VERSION ""

NS_ :

BS_:

BU_: CAEB TCU GW
VAL_TABLE_ MotorRunningStatus 1 "MOTOR_RUNNING" 0 "MOTOR_OFF" ;

BO_ 2147536897 msgVD_GNSS_precision_position: 16 CAEB
 SG_ sigVD_GNSS_LatitudeDegree : 4|32@1+ (1E-07,0) [0|134.217727] "DegOfArc" Vector__XXX
 SG_ sigVD_GNSS_LongitudeDegree : 36|32@1+ (1E-07,0) [0|268.435455] "DegOfArc" Vector__XXX
 SG_ sigVD_GNSS_heading : 68|12@1+ (0.1,0) [0|360.1] "" Vector__XXX

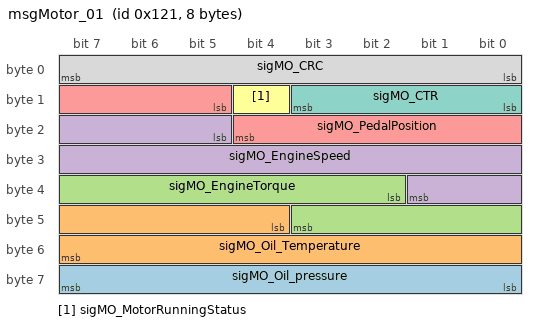
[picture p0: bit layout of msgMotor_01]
BO_ 289 msgMotor_01: 8 Vector__XXX
 SG_ sigMO_Oil_pressure : 56|8@1+ (1,0) [0|255] "" Vector__XXX
 SG_ sigMO_Oil_Temperature : 44|12@1+ (0.04,-30) [-30|133.8] "" Vector__XXX
 SG_ sigMO_EngineTorque : 34|10@1+ (1,0) [0|1023] "Nm"  GW,TCU
 SG_ sigMO_EngineSpeed : 21|13@1+ (1,0) [0|8191] "rpm"  GW,TCU
 SG_ sigMO_PedalPosition : 13|8@1+ (0.4,0) [0|100] "Percent"  GW,TCU
 SG_ sigMO_MotorRunningStatus : 12|1@1+ (1,0) [0|1] ""  TCU,GW
 SG_ sigMO_CTR : 8|4@1+ (1,0) [0|15] ""  TCU,GW
 SG_ sigMO_CRC : 0|8@1+ (1,0) [0|255] ""  TCU,GW

CM_ SG_ 2147536897 sigVD_GNSS_LatitudeDegree "Latitude (north-south value)";
CM_ SG_ 2147536897 sigVD_GNSS_LongitudeDegree "Longitude (east-west value)\n";
CM_ SG_ 289 sigMO_EngineTorque "Actual state of engine torque";
CM_ SG_ 289 sigMO_EngineSpeed "Actual speed of engine shaft";
CM_ SG_ 289 sigMO_PedalPosition "Actual possition of gas pedal";
CM_ SG_ 289 sigMO_MotorRunningStatus "Actual state of diesel engine";
CM_ SG_ 289 sigMO_CTR "4-bit message counter";
CM_ SG_ 289 sigMO_CRC "8-bit message checksum";
BA_DEF_ BO_  "VFrameFormat" ENUM  "StandardCAN","ExtendedCAN","reserved","reserved","reserved","reserved","reserved","reserved","reserved","reserved","reserved","reserved","reserved","reserved","StandardCAN_FD","ExtendedCAN_FD";
BA_DEF_ BO_  "GenMsgStartDelayTime" INT 0 65535;
BA_DEF_ BO_  "GenMsgSendType" ENUM  "Cyclic","NotUsed","NotUsed","NotUsed","NotUsed","NotUsed","NotUsed","IfActive","NoMsgSendType","NotUsed","vector_leerstring";
BA_DEF_ BO_  "GenMsgCycleTime" INT 0 50000;
BA_DEF_ SG_  "GenSigSendType" ENUM  "Cyclic","OnWrite","OnWriteWithRepetition","OnChange","OnChangeWithRepetition","IfActive","IfActiveWithRepetition","NoSigSendType","NotUsed","NotUsed","NotUsed","NotUsed","NotUsed";
BA_DEF_ SG_  "GenSigStartValue" FLOAT 0 100000000000;
BA_DEF_DEF_  "VFrameFormat" "ExtendedCAN_FD";
BA_DEF_DEF_  "GenMsgStartDelayTime" 0;
BA_DEF_DEF_  "GenMsgSendType" "NoMsgSendType";
BA_DEF_DEF_  "GenMsgCycleTime" 0;
BA_DEF_DEF_  "GenSigSendType" "Cyclic";
BA_DEF_DEF_  "GenSigStartValue" 0;
BA_ "GenMsgSendType" BO_ 2147536897 7;
BA_ "GenMsgStartDelayTime" BO_ 2147536897 1;
BA_ "VFrameFormat" BO_ 289 0;
BA_ "GenMsgCycleTime" BO_ 289 100;
BA_ "GenMsgStartDelayTime" BO_ 289 100;
BA_ "GenMsgSendType" BO_ 289 0;
BA_ "GenSigStartValue" SG_ 2147536897 sigVD_GNSS_LatitudeDegree 1342177260;
BA_ "GenSigSendType" SG_ 2147536897 sigVD_GNSS_LatitudeDegree 7;
BA_ "GenSigStartValue" SG_ 2147536897 sigVD_GNSS_LongitudeDegree 2684354540;
BA_ "GenSigSendType" SG_ 2147536897 sigVD_GNSS_LongitudeDegree 7;
BA_ "GenSigStartValue" SG_ 2147536897 sigVD_GNSS_heading 3601;
BA_ "GenSigSendType" SG_ 2147536897 sigVD_GNSS_heading 7;
BA_ "GenSigStartValue" SG_ 289 sigMO_Oil_Temperature 750;
BA_ "GenSigSendType" SG_ 289 sigMO_MotorRunningStatus 7;
BA_ "GenSigSendType" SG_ 289 sigMO_CTR 7;
BA_ "GenSigSendType" SG_ 289 sigMO_CRC 7;
VAL_ 289 sigMO_MotorRunningStatus 1 "MOTOR_RUNNING" 0 "MOTOR_OFF" ;
